VERSION "HIPBNYYYYYYYYYYYYYYYYYYYYYYYYYYYYYYYYYYYYY/4/%%%/4/'%**4YYY///"

NS_ :

BS_:

BU_:

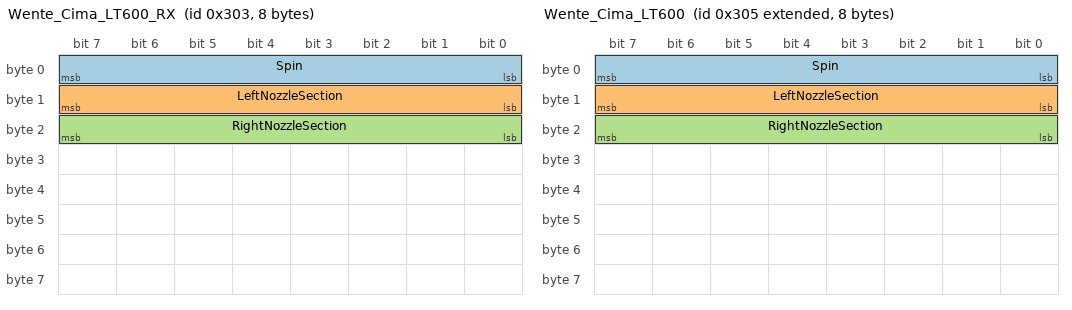
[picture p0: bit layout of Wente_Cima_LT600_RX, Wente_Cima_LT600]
BO_ 771 Wente_Cima_LT600_RX: 8 Vector__XXX
 SG_ Spin : 0|8@1+ (1,0) [0|0] "True/False" Vector__XXX
 SG_ LeftNozzleSection : 8|8@1+ (1,0) [0|0] "True/False" Vector__XXX
 SG_ RightNozzleSection : 16|8@1+ (1,0) [0|0] "True/False" Vector__XXX

BO_ 2147484421 Wente_Cima_LT600: 8 Vector__XXX
 SG_ Spin : 0|8@1+ (1,0) [0|0] "True/False" Vector__XXX
 SG_ LeftNozzleSection : 8|8@1+ (1,0) [0|0] "True/False" Vector__XXX
 SG_ RightNozzleSection : 16|8@1+ (1,0) [0|0] "True/False" Vector__XXX
